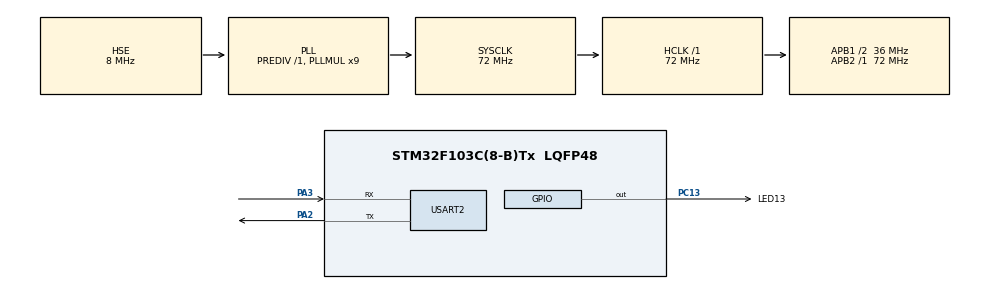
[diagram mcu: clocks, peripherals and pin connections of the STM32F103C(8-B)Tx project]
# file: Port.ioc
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FREERTOS.Tasks01=defaultTask,0,128,StartDefaultTask,Default,NULL,Dynamic,NULL,NULL
FREERTOS.configMAX_PRIORITIES=20
Mcu.Family=STM32F1
Mcu.Name=STM32F103C(8-B)Tx
Mcu.Package=LQFP48
NVIC.PriorityGroup=NVIC_PRIORITYGROUP_4
PA2.Mode=Asynchronous
PA2.Signal=USART2_TX
PA3.Mode=Asynchronous
PA3.Signal=USART2_RX
PC13-TAMPER-RTC.GPIO_Label=LED13
PC13-TAMPER-RTC.GPIO_Speed=GPIO_SPEED_FREQ_HIGH
PC13-TAMPER-RTC.Signal=GPIO_Output
PC14-OSC32_IN.Mode=LSE-External-Oscillator
PC14-OSC32_IN.Signal=RCC_OSC32_IN
PC15-OSC32_OUT.Mode=LSE-External-Oscillator
PC15-OSC32_OUT.Signal=RCC_OSC32_OUT
PD0-OSC_IN.Mode=HSE-External-Oscillator
PD0-OSC_IN.Signal=RCC_OSC_IN
PD1-OSC_OUT.Mode=HSE-External-Oscillator
PD1-OSC_OUT.Signal=RCC_OSC_OUT
ProjectManager.HeapSize=0x200
ProjectManager.StackSize=0x400
ProjectManager.TargetToolchain=STM32CubeIDE
RCC.AHBFreq_Value=72000000
RCC.APB1CLKDivider=RCC_HCLK_DIV2
RCC.APB1Freq_Value=36000000
RCC.APB1TimFreq_Value=72000000
RCC.APB2Freq_Value=72000000
RCC.APB2TimFreq_Value=72000000
RCC.HCLKFreq_Value=72000000
RCC.PLLMUL=RCC_PLL_MUL9
RCC.PLLSourceVirtual=RCC_PLLSOURCE_HSE
RCC.SYSCLKFreq_VALUE=72000000
RCC.SYSCLKSource=RCC_SYSCLKSOURCE_PLLCLK
RCC.USBFreq_Value=72000000
USART2.VirtualMode=VM_ASYNC
VP_FREERTOS_VS_CMSIS_V1.Mode=CMSIS_V1
board=custom

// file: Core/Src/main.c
/* USER CODE BEGIN Header */
/**
  ******************************************************************************
  * @file           : main.c
  * @brief          : Main program body
  ******************************************************************************
  * @attention
  *
  * Copyright (c) 2023 STMicroelectronics.
  * All rights reserved.
  *
  * This software is licensed under terms that can be found in the LICENSE file
  * in the root directory of this software component.
  * If no LICENSE file comes with this software, it is provided AS-IS.
  *
  ******************************************************************************
  */
/* USER CODE END Header */
#include "main.h"
#include "cmsis_os.h"

UART_HandleTypeDef huart2;

osThreadId defaultTaskHandle;

void SystemClock_Config(void);
static void MX_GPIO_Init(void);
static void MX_USART2_UART_Init(void);
void StartDefaultTask(void const * argument);

int main(void)
{

  /* MCU Configuration--------------------------------------------------------*/

  /* Reset of all peripherals, Initializes the Flash interface and the Systick. */
  HAL_Init();

  /* Configure the system clock */
  SystemClock_Config();

  /* Initialize all configured peripherals */
  MX_GPIO_Init();
  MX_USART2_UART_Init();
  /* USER CODE BEGIN 2 */
printf("Hello world\n");
  /* USER CODE END 2 */

  /* Create the thread(s) */
  /* definition and creation of defaultTask */
  osThreadDef(defaultTask, StartDefaultTask, osPriorityNormal, 0, 128);
  defaultTaskHandle = osThreadCreate(osThread(defaultTask), NULL);

  /* Start scheduler */
  osKernelStart();

  /* We should never get here as control is now taken by the scheduler */
  /* Infinite loop */
  while (1)
  {

  }
}

void SystemClock_Config(void)
{
  RCC_OscInitTypeDef RCC_OscInitStruct = {0};
  RCC_ClkInitTypeDef RCC_ClkInitStruct = {0};

  /** Initializes the RCC Oscillators according to the specified parameters
  * in the RCC_OscInitTypeDef structure.
  */
  RCC_OscInitStruct.OscillatorType = RCC_OSCILLATORTYPE_HSE;
  RCC_OscInitStruct.HSEState = RCC_HSE_ON;
  RCC_OscInitStruct.HSEPredivValue = RCC_HSE_PREDIV_DIV1;
  RCC_OscInitStruct.HSIState = RCC_HSI_ON;
  RCC_OscInitStruct.PLL.PLLState = RCC_PLL_ON;
  RCC_OscInitStruct.PLL.PLLSource = RCC_PLLSOURCE_HSE;
  RCC_OscInitStruct.PLL.PLLMUL = RCC_PLL_MUL9;
  if (HAL_RCC_OscConfig(&RCC_OscInitStruct) != HAL_OK)
  {
    Error_Handler();
  }

  /** Initializes the CPU, AHB and APB buses clocks
  */
  RCC_ClkInitStruct.ClockType = RCC_CLOCKTYPE_HCLK|RCC_CLOCKTYPE_SYSCLK
                              |RCC_CLOCKTYPE_PCLK1|RCC_CLOCKTYPE_PCLK2;
  RCC_ClkInitStruct.SYSCLKSource = RCC_SYSCLKSOURCE_PLLCLK;
  RCC_ClkInitStruct.AHBCLKDivider = RCC_SYSCLK_DIV1;
  RCC_ClkInitStruct.APB1CLKDivider = RCC_HCLK_DIV2;
  RCC_ClkInitStruct.APB2CLKDivider = RCC_HCLK_DIV1;

  if (HAL_RCC_ClockConfig(&RCC_ClkInitStruct, FLASH_LATENCY_2) != HAL_OK)
  {
    Error_Handler();
  }
}

static void MX_USART2_UART_Init(void)
{

  huart2.Instance = USART2;
  huart2.Init.BaudRate = 115200;
  huart2.Init.WordLength = UART_WORDLENGTH_8B;
  huart2.Init.StopBits = UART_STOPBITS_1;
  huart2.Init.Parity = UART_PARITY_NONE;
  huart2.Init.Mode = UART_MODE_TX_RX;
  huart2.Init.HwFlowCtl = UART_HWCONTROL_NONE;
  huart2.Init.OverSampling = UART_OVERSAMPLING_16;
  if (HAL_UART_Init(&huart2) != HAL_OK)
  {
    Error_Handler();
  }

}

static void MX_GPIO_Init(void)
{
  GPIO_InitTypeDef GPIO_InitStruct = {0};

  /* GPIO Ports Clock Enable */
  __HAL_RCC_GPIOC_CLK_ENABLE();
  __HAL_RCC_GPIOD_CLK_ENABLE();
  __HAL_RCC_GPIOA_CLK_ENABLE();

  /*Configure GPIO pin Output Level */
  HAL_GPIO_WritePin(LED13_GPIO_Port, LED13_Pin, GPIO_PIN_RESET);

  /*Configure GPIO pin : LED13_Pin */
  GPIO_InitStruct.Pin = LED13_Pin;
  GPIO_InitStruct.Mode = GPIO_MODE_OUTPUT_PP;
  GPIO_InitStruct.Pull = GPIO_NOPULL;
  GPIO_InitStruct.Speed = GPIO_SPEED_FREQ_HIGH;
  HAL_GPIO_Init(LED13_GPIO_Port, &GPIO_InitStruct);

}

void StartDefaultTask(void const * argument)
{
  /* USER CODE BEGIN 5 */
  /* Infinite loop */
  for(;;)
  {
	  HAL_GPIO_TogglePin(LED13_GPIO_Port,LED13_Pin);
	  HAL_Delay(1000);
    osDelay(1);
  }
  /* USER CODE END 5 */
}

void Error_Handler(void)
{
  __disable_irq();
  while (1)
  {
  }
}
